# GBA register map
Vendor: Nintendo; Series: Game Boy; File version: 1.0
CPU: ARM7TDMI r4p1, little endian, no MPU, no FPU, I-cache, vendor SysTick, 0 interrupt priority bits
Registers are 16-bit, read-write, reset 0x0 unless marked. A register's access mark holds for its fields unless they carry their own. Offsets are from the block's base; [hi:lo] are bit positions; {n}, {i} and the like mark numbered series.

## LCD_I/O_Registers
Base 0x04000000
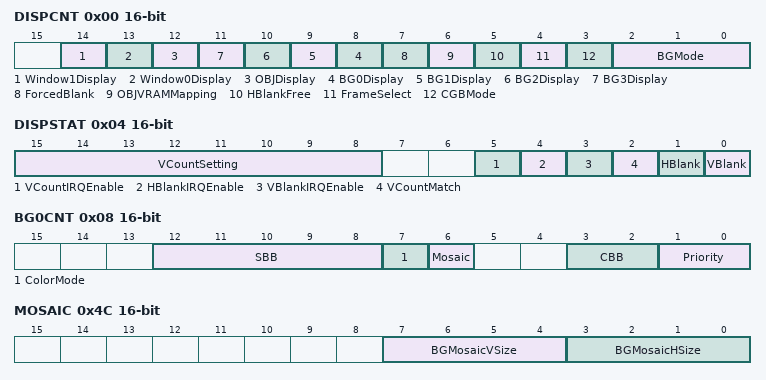
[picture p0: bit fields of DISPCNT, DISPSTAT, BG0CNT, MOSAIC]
0x00 DISPCNT — LCD Control
  [14] Window1Display — Enables window 1.
    0=Off; 1=On
  [13] Window0Display — Enables window 0.
    0=Off; 1=On
  [12] OBJDisplay — Enables display of sprites.
    0=Off; 1=On
  [n+8] BG{n}Display (n=0..3) — Enables display of background layer {n}.
    0=Off; 1=On
  [7] ForcedBlank — Forces the display into blank mode when set.
    0=Normal; 1=Allow FAST access to VRAM, Palette, OAM
  [6] OBJVRAMMapping — Selects the OBJ character VRAM mapping mode.
    0=Two dimensional; 1=One dimensional
  [5] HBlankFree — Allows OAM access during H-Blank when set.
    0=Normal; 1=Allow access to OAM during H-Blank
  [4] FrameSelect — Selects the displayed framebuffer.
    0=Frame 0
  [3] CGBMode ro — Selects GBA or CGB compatibility mode.
    0=GBA; 1=CGB; can be set only by BIOS opcodes
  [2:0] BGMode — Background mode selection.
    {v}=Mode {v} (v=0..5)
0x02 STEREO_3D — Undocumented stereo 3D / green swap register
  [0] STEREO_3D — Undocumented stereoscopic display enable; historically known as GREEN_SWAP
    0=Disabled; 1=Enabled
0x04 DISPSTAT — General LCD Status (STAT,LYC)
  [15:8] VCountSetting — Scanline used for the V-counter comparison.
  [5] VCountIRQEnable — Enables a V-counter interrupt.
  [4] HBlankIRQEnable — Enables an H-Blank interrupt.
  [3] VBlankIRQEnable — Enables a V-Blank interrupt.
  [2] VCountMatch — Indicates that the current scanline matches the comparison value.
  [1] HBlank — Indicates that the LCD is in H-Blank.
    0=HBlank
  [0] VBlank — Indicates that the LCD is in V-Blank.
    0=VBlank
0x06 VCOUNT ro — Vertical Counter (LY)
0x08 BG0CNT — BG0 Control
  [12:8] SBB — Tile-map screen base block, in 2 KiB units.
    0=BG Map Data
  [7] ColorMode — Selects 16-color or 256-color tiles.
    0=16/16; 1=256/1
  [6] Mosaic — Enables mosaic processing for this background.
    0=Disabled; 1=Enabled
  [3:2] CBB — Tile-data character base block, in 16 KiB units.
    0=BG Tile Data
  [1:0] Priority — BG priority relative to other backgrounds.
    0=Highest
{0x8+2i} BG{i}CNT (i=1..3) — BG{i} Control
{0x10+4i} BG{i}HOFS wo (i=0..3) — BG{i} X-Offset
{0x12+4i} BG{i}VOFS wo (i=0..3) — BG{i} Y-Offset
0x20 BG2PA wo — BG2 rotation/scaling parameter A (dx), signed 8.8 fixed-point.
  [15:0] BG2PA — Signed 8.8 fixed-point rotation/scaling parameter A (dx).
0x22 BG2PB wo — BG2 rotation/scaling parameter B (dmx), signed 8.8 fixed-point.
  [15:0] BG2PB — Signed 8.8 fixed-point rotation/scaling parameter B (dmx).
0x24 BG2PC wo — BG2 rotation/scaling parameter C (dy), signed 8.8 fixed-point.
  [15:0] BG2PC — Signed 8.8 fixed-point rotation/scaling parameter C (dy).
0x26 BG2PD wo — BG2 rotation/scaling parameter D (dmy), signed 8.8 fixed-point.
  [15:0] BG2PD — Signed 8.8 fixed-point rotation/scaling parameter D (dmy).
0x28 BG2X 32-bit wo — BG2 reference point X-coordinate, signed 19.8 fixed-point.
  [31:0] BG2X — Signed 19.8 fixed-point BG2 reference point X-coordinate.
0x2C BG2Y 32-bit wo — BG2 reference point Y-coordinate, signed 19.8 fixed-point.
  [31:0] BG2Y — Signed 19.8 fixed-point BG2 reference point Y-coordinate.
0x30 BG3PA wo — BG3 rotation/scaling parameter A (dx), signed 8.8 fixed-point.
  [15:0] BG3PA — Signed 8.8 fixed-point rotation/scaling parameter A (dx).
0x32 BG3PB wo — BG3 rotation/scaling parameter B (dmx), signed 8.8 fixed-point.
  [15:0] BG3PB — Signed 8.8 fixed-point rotation/scaling parameter B (dmx).
0x34 BG3PC wo — BG3 rotation/scaling parameter C (dy), signed 8.8 fixed-point.
  [15:0] BG3PC — Signed 8.8 fixed-point rotation/scaling parameter C (dy).
0x36 BG3PD wo — BG3 rotation/scaling parameter D (dmy), signed 8.8 fixed-point.
  [15:0] BG3PD — Signed 8.8 fixed-point rotation/scaling parameter D (dmy).
0x38 BG3X 32-bit wo — BG3 reference point X-coordinate, signed 19.8 fixed-point.
  [31:0] BG3X — Signed 19.8 fixed-point BG3 reference point X-coordinate.
0x3C BG3Y 32-bit wo — BG3 reference point Y-coordinate, signed 19.8 fixed-point.
  [31:0] BG3Y — Signed 19.8 fixed-point BG3 reference point Y-coordinate.
0x40 WIN0H wo — Window 0 Horizontal Dimensions
0x42 WIN1H wo — Window 1 Horizontal Dimensions
0x44 WIN0V wo — Window 0 Vertical Dimensions
0x46 WIN1V wo — Window 1 Vertical Dimensions
0x48 WININ — Inside of Window 0 and 1
0x4A WINOUT — Inside of OBJ Window & Outside of Windows
0x4C MOSAIC wo — Mosaic Size
  [7:4] BGMosaicVSize — Vertical mosaic size for background layers.
  [3:0] BGMosaicHSize — Horizontal mosaic size for background layers.
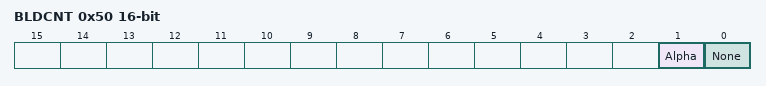
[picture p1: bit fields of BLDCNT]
0x50 BLDCNT — Color Special Effects Selection
  [1] Alpha Blending — Selects alpha blending as the color special effect.
  [0] None — No color special effect is selected.
0x52 BLDALPHA — Alpha Blending Coefficients
0x54 BLDY wo — Brightness (Fade-In/Out) Coefficient
